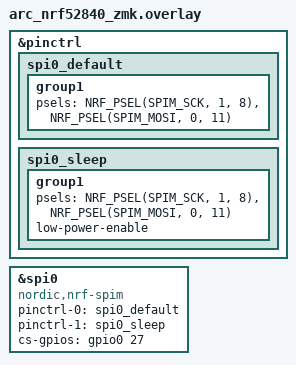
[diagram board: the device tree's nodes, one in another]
/*
 * Copyright (c) 2022 The ZMK Contributors
 *
 * SPDX-License-Identifier: MIT
 */

&pinctrl {
    spi0_default: spi0_default {
        group1 {
            psels = <NRF_PSEL(SPIM_SCK, 1, 8)>,
                <NRF_PSEL(SPIM_MOSI, 0, 11)>;
        };
    };

    spi0_sleep: spi0_sleep {
        group1 {
            psels = <NRF_PSEL(SPIM_SCK, 1, 8)>,
                <NRF_PSEL(SPIM_MOSI, 0, 11)>;
            low-power-enable;
        };
    };
};

nice_view_spi: &spi0 {
    compatible = "nordic,nrf-spim";
    pinctrl-0 = <&spi0_default>;
    pinctrl-1 = <&spi0_sleep>;
    pinctrl-names = "default", "sleep";
    cs-gpios = <&gpio0 27 GPIO_ACTIVE_HIGH>;
};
